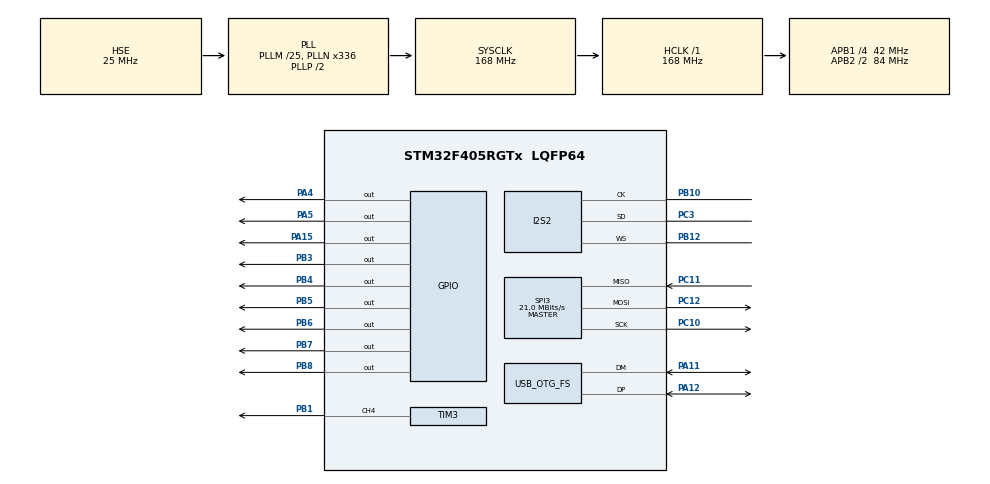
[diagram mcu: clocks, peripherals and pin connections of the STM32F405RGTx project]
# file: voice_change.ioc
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Dma.Request0=SPI2_RX
Dma.SPI2_RX.0.Direction=DMA_PERIPH_TO_MEMORY
Dma.SPI2_RX.0.FIFOMode=DMA_FIFOMODE_DISABLE
Dma.SPI2_RX.0.Instance=DMA1_Stream3
Dma.SPI2_RX.0.MemDataAlignment=DMA_MDATAALIGN_HALFWORD
Dma.SPI2_RX.0.MemInc=DMA_MINC_ENABLE
Dma.SPI2_RX.0.Mode=DMA_NORMAL
Dma.SPI2_RX.0.PeriphDataAlignment=DMA_PDATAALIGN_HALFWORD
Dma.SPI2_RX.0.PeriphInc=DMA_PINC_DISABLE
Dma.SPI2_RX.0.Priority=DMA_PRIORITY_HIGH
I2S2.AudioFreq=I2S_AUDIOFREQ_16K
I2S2.DataFormat=I2S_DATAFORMAT_24B
I2S2.ErrorAudioFreq=-0.35 %
I2S2.FullDuplexMode=I2S_FULLDUPLEXMODE_DISABLE
I2S2.Instance=SPI$Index
I2S2.Mode=I2S_MODE_MASTER_RX
I2S2.RealAudioFreq=15.943 KHz
I2S2.VirtualMode=I2S_MODE_MASTER
Mcu.Family=STM32F4
Mcu.Name=STM32F405RGTx
Mcu.Package=LQFP64
NVIC.DMA1_Stream3_IRQn=true\:0\:0\:false\:false\:true\:false\:true\:true
NVIC.OTG_FS_IRQn=true\:0\:0\:false\:false\:true\:false\:true\:true
NVIC.PriorityGroup=NVIC_PRIORITYGROUP_4
NVIC.SPI2_IRQn=true\:0\:0\:false\:false\:true\:true\:true\:true
NVIC.TIM2_IRQn=true\:0\:0\:false\:false\:true\:true\:true\:true
PA11.Mode=Device_Only
PA11.Signal=USB_OTG_FS_DM
PA12.GPIO_Mode=GPIO_MODE_AF_PP
PA12.GPIO_PuPd=GPIO_NOPULL
PA12.GPIO_Speed=GPIO_SPEED_FREQ_VERY_HIGH
PA12.Mode=Device_Only
PA12.Signal=USB_OTG_FS_DP
PA13.Mode=Serial_Wire
PA13.Signal=SYS_JTMS-SWDIO
PA14.Mode=Serial_Wire
PA14.Signal=SYS_JTCK-SWCLK
PA15.Signal=GPIO_Output
PA4.Signal=GPIO_Output
PA5.Signal=GPIO_Output
PB1.Signal=S_TIM3_CH4
PB10.Mode=Half_Duplex_Master
PB10.Signal=I2S2_CK
PB12.Mode=Half_Duplex_Master
PB12.Signal=I2S2_WS
PB3.Signal=GPIO_Output
PB4.Signal=GPIO_Output
PB5.Signal=GPIO_Output
PB6.GPIO_ModeDefaultOutputPP=GPIO_MODE_OUTPUT_PP
PB6.GPIO_PuPd=GPIO_NOPULL
PB6.Signal=GPIO_Output
PB7.GPIO_ModeDefaultOutputPP=GPIO_MODE_OUTPUT_PP
PB7.GPIO_PuPd=GPIO_NOPULL
PB7.GPIO_Speed=GPIO_SPEED_FREQ_HIGH
PB7.Signal=GPIO_Output
PB8.GPIO_ModeDefaultOutputPP=GPIO_MODE_OUTPUT_PP
PB8.GPIO_PuPd=GPIO_NOPULL
PB8.GPIO_Speed=GPIO_SPEED_FREQ_HIGH
PB8.Signal=GPIO_Output
PC10.Mode=Full_Duplex_Master
PC10.Signal=SPI3_SCK
PC11.Mode=Full_Duplex_Master
PC11.Signal=SPI3_MISO
PC12.Mode=Full_Duplex_Master
PC12.Signal=SPI3_MOSI
PC3.Mode=Half_Duplex_Master
PC3.Signal=I2S2_SD
PH0-OSC_IN.Mode=HSE-External-Oscillator
PH0-OSC_IN.Signal=RCC_OSC_IN
PH1-OSC_OUT.Mode=HSE-External-Oscillator
PH1-OSC_OUT.Signal=RCC_OSC_OUT
ProjectManager.HeapSize=0x4000
ProjectManager.StackSize=0x1000
ProjectManager.TargetToolchain=MDK-ARM V5.32
RCC.48MHZClocksFreq_Value=48000000
RCC.AHBFreq_Value=168000000
RCC.APB1CLKDivider=RCC_HCLK_DIV4
RCC.APB1Freq_Value=42000000
RCC.APB1TimFreq_Value=84000000
RCC.APB2CLKDivider=RCC_HCLK_DIV2
RCC.APB2Freq_Value=84000000
RCC.APB2TimFreq_Value=168000000
RCC.CortexFreq_Value=168000000
RCC.HCLKFreq_Value=168000000
RCC.HSE_VALUE=25000000
RCC.HSI_VALUE=16000000
RCC.LSE_VALUE=32768
RCC.PLLI2SN=100
RCC.PLLM=25
RCC.PLLN=336
RCC.PLLQ=7
RCC.SYSCLKFreq_VALUE=168000000
RCC.SYSCLKSource=RCC_SYSCLKSOURCE_PLLCLK
RCC.VCOOutputFreq_Value=336000000
SH.S_TIM3_CH4.0=TIM3_CH4,PWM Generation4 CH4
SPI3.CLKPolarity=SPI_POLARITY_HIGH
SPI3.CalculateBaudRate=21.0 MBits/s
SPI3.DataSize=SPI_DATASIZE_16BIT
SPI3.Direction=SPI_DIRECTION_2LINES
SPI3.Mode=SPI_MODE_MASTER
SPI3.VirtualType=VM_MASTER
TIM2.Period=100-1
TIM2.Prescaler=840-1
TIM3.Channel-PWM\ Generation4\ CH4=TIM_CHANNEL_4
USB_DEVICE.CLASS_NAME_FS=AUDIO
USB_DEVICE.PID_AUDIO_FS=0x5730
USB_DEVICE.USBD_AUDIO_FREQ-AUDIO_FS=16000
USB_DEVICE.USBD_DEBUG_LEVEL-AUDIO_FS=0
USB_DEVICE.USBD_MAX_NUM_INTERFACES-AUDIO_FS=3
USB_DEVICE.VirtualMode-AUDIO_FS=Audio
USB_DEVICE.VirtualModeFS=Audio_FS
USB_OTG_FS.VirtualMode=Device_Only
VP_TIM2_VS_ClockSourceINT.Mode=Internal
VP_TIM3_VS_ClockSourceINT.Mode=Internal
VP_USB_DEVICE_VS_USB_DEVICE_AUDIO_FS.Mode=AUDIO_FS
board=custom

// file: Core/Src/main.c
/* USER CODE BEGIN Header */
/**
 ******************************************************************************
 * @file           : main.c
 * @brief          : Main program body
 ******************************************************************************
 * @attention
 *
 * Copyright (c) 2024 STMicroelectronics.
 * All rights reserved.
 *
 * This software is licensed under terms that can be found in the LICENSE file
 * in the root directory of this software component.
 * If no LICENSE file comes with this software, it is provided AS-IS.
 *
 ******************************************************************************
 */
/* USER CODE END Header */
#include "main.h"
#include "dma.h"
#include "i2s.h"
#include "spi.h"
#include "tim.h"
#include "usb_device.h"
#include "gpio.h"

/* USER CODE BEGIN Includes */
#include "ST7735s.h"
#include "I2S_MC.h"
#include "LED.h"
#include "usb_buffer_part.h"
#include "LCD.h"
/* USER CODE END Includes */

void SystemClock_Config(void);

/* USER CODE BEGIN 0 */

// I2S--text
uint8_t xstr=0;
uint8_t ystr=0;
/* USER CODE END 0 */

int main(void)
{

  /* MCU Configuration--------------------------------------------------------*/

  /* Reset of all peripherals, Initializes the Flash interface and the Systick. */
  HAL_Init();

  /* Configure the system clock */
  SystemClock_Config();

  /* Initialize all configured peripherals */
  MX_GPIO_Init();
  MX_DMA_Init();
  MX_TIM2_Init();
  MX_USB_DEVICE_Init();
  MX_SPI3_Init();
  MX_I2S2_Init();
  MX_TIM3_Init();
  /* USER CODE BEGIN 2 */
  LED_Init();

  LCD_Init();

	MicroPhone_Init();
  // LED--GPIO

  // MICROPHONE----I2S

  /* USER CODE END 2 */

  /* Infinite loop */
  /* USER CODE BEGIN WHILE */

  while (1)
  {
  LCD_Fill(xstr, ystr, xstr+160, ystr+80, WHITE);
  LED_run();
    /* USER CODE END WHILE */

  }
}

void SystemClock_Config(void)
{
  RCC_OscInitTypeDef RCC_OscInitStruct = {0};
  RCC_ClkInitTypeDef RCC_ClkInitStruct = {0};

  /** Configure the main internal regulator output voltage
  */
  __HAL_RCC_PWR_CLK_ENABLE();
  __HAL_PWR_VOLTAGESCALING_CONFIG(PWR_REGULATOR_VOLTAGE_SCALE1);

  /** Initializes the RCC Oscillators according to the specified parameters
  * in the RCC_OscInitTypeDef structure.
  */
  RCC_OscInitStruct.OscillatorType = RCC_OSCILLATORTYPE_HSE;
  RCC_OscInitStruct.HSEState = RCC_HSE_ON;
  RCC_OscInitStruct.PLL.PLLState = RCC_PLL_ON;
  RCC_OscInitStruct.PLL.PLLSource = RCC_PLLSOURCE_HSE;
  RCC_OscInitStruct.PLL.PLLM = 25;
  RCC_OscInitStruct.PLL.PLLN = 336;
  RCC_OscInitStruct.PLL.PLLP = RCC_PLLP_DIV2;
  RCC_OscInitStruct.PLL.PLLQ = 7;
  if (HAL_RCC_OscConfig(&RCC_OscInitStruct) != HAL_OK)
  {
    Error_Handler();
  }

  /** Initializes the CPU, AHB and APB buses clocks
  */
  RCC_ClkInitStruct.ClockType = RCC_CLOCKTYPE_HCLK|RCC_CLOCKTYPE_SYSCLK
                              |RCC_CLOCKTYPE_PCLK1|RCC_CLOCKTYPE_PCLK2;
  RCC_ClkInitStruct.SYSCLKSource = RCC_SYSCLKSOURCE_PLLCLK;
  RCC_ClkInitStruct.AHBCLKDivider = RCC_SYSCLK_DIV1;
  RCC_ClkInitStruct.APB1CLKDivider = RCC_HCLK_DIV4;
  RCC_ClkInitStruct.APB2CLKDivider = RCC_HCLK_DIV2;

  if (HAL_RCC_ClockConfig(&RCC_ClkInitStruct, FLASH_LATENCY_5) != HAL_OK)
  {
    Error_Handler();
  }
}

void Error_Handler(void)
{
  __disable_irq();
  while (1)
  {
  }
}
